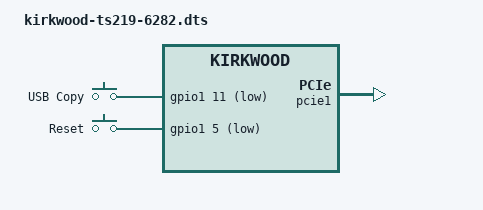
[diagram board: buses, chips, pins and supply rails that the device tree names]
// SPDX-License-Identifier: GPL-2.0
/dts-v1/;

#include "kirkwood.dtsi"
#include "kirkwood-6282.dtsi"
#include "kirkwood-ts219.dtsi"

/ {
	ocp@f1000000 {
		pinctrl: pin-controller@10000 {

			pinctrl-0 = <&pmx_ram_size &pmx_board_id>;
			pinctrl-names = "default";

			pmx_ram_size: pmx-ram-size {
				/* RAM: 0: 256 MB, 1: 512 MB */
				marvell,pins = "mpp36";
				marvell,function = "gpio";
			};
			pmx_reset_button: pmx-reset-button {
				marvell,pins = "mpp37";
				marvell,function = "gpio";
			};
			pmx_USB_copy_button: pmx-USB-copy-button {
				marvell,pins = "mpp43";
				marvell,function = "gpio";
			};
			pmx_board_id: pmx-board-id {
				/* 0: TS-11x, 1: TS-21x */
				marvell,pins = "mpp44";
				marvell,function = "gpio";
			};
		};
	};

	gpio_keys {
		compatible = "gpio-keys";
		#address-cells = <1>;
		#size-cells = <0>;
		pinctrl-0 = <&pmx_reset_button &pmx_USB_copy_button>;
		pinctrl-names = "default";

		copy {
			label = "USB Copy";
			linux,code = <KEY_COPY>;
			gpios = <&gpio1 11 GPIO_ACTIVE_LOW>;
		};
		reset {
			label = "Reset";
			linux,code = <KEY_RESTART>;
			gpios = <&gpio1 5 GPIO_ACTIVE_LOW>;
		};
	};
};

&ethphy0 { reg = <0>; };

&pcie1 { status = "okay"; };
